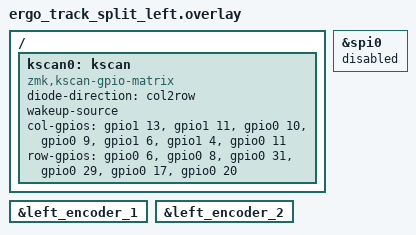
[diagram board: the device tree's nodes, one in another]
/*
 * Copyright (c) 2024
 * SPDX-License-Identifier: MIT
 */

#include "ergo_track_split.dtsi"

/ {
    kscan0: kscan {
        compatible = "zmk,kscan-gpio-matrix";
        diode-direction = "col2row";
        wakeup-source;

        col-gpios
            = <&gpio1 13 GPIO_ACTIVE_HIGH>
            , <&gpio1 11 GPIO_ACTIVE_HIGH>
            , <&gpio0 10 GPIO_ACTIVE_HIGH>
            , <&gpio0 9 GPIO_ACTIVE_HIGH>
            , <&gpio1 6 GPIO_ACTIVE_HIGH>
            , <&gpio1 4 GPIO_ACTIVE_HIGH>
            , <&gpio0 11 GPIO_ACTIVE_HIGH>;

        row-gpios
            = <&gpio0 6 (GPIO_ACTIVE_HIGH | GPIO_PULL_DOWN)>
            , <&gpio0 8 (GPIO_ACTIVE_HIGH | GPIO_PULL_DOWN)>
            , <&gpio0 31 (GPIO_ACTIVE_HIGH | GPIO_PULL_DOWN)>
            , <&gpio0 29 (GPIO_ACTIVE_HIGH | GPIO_PULL_DOWN)>
            , <&gpio0 17 (GPIO_ACTIVE_HIGH | GPIO_PULL_DOWN)>
            , <&gpio0 20 (GPIO_ACTIVE_HIGH | GPIO_PULL_DOWN)>;
    };
};

&left_encoder_1 { status = "okay"; };
&left_encoder_2 { status = "okay"; };

&spi0 { status = "disabled"; };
